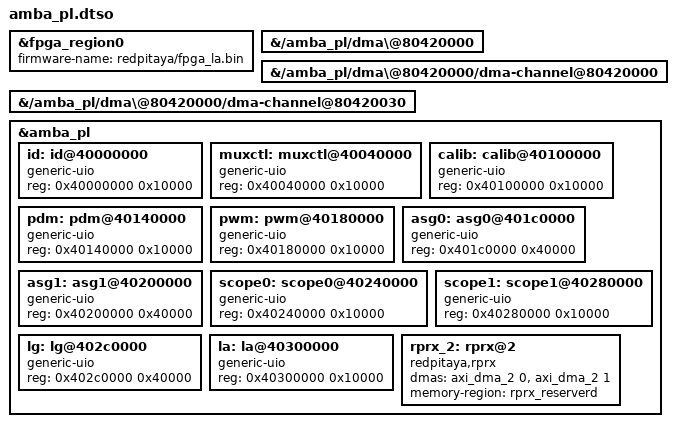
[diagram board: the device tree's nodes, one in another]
/dts-v1/;
/plugin/;
/{
		fragment@0 {
				target = <&fpga_region0>;
				#address-cells = <1>;
				#size-cells = <1>;

				__overlay__ {
					#address-cells = <1>;
					#size-cells = <1>;
					firmware-name = "redpitaya/fpga_la.bin";
				};
		};
		
		fragment@1 {
		target-path = "/amba_pl/dma\@80420000";
			__overlay__ {
						status = "okay";
				};
		};
		fragment@2 {
		target-path = "/amba_pl/dma\@80420000/dma-channel@80420000";
			__overlay__ {
						status = "okay";
				};
		};
		fragment@3 {
		target-path = "/amba_pl/dma\@80420000/dma-channel@80420030";
			__overlay__ {
						status = "okay";
				};
		};
		fragment@4{
			target = <&amba_pl>;
			__overlay__ {
				id: id@40000000 {
					compatible = "generic-uio";
					reg = <0x40000000 0x10000>;
					status = "okay";
					};
			};
		};
		fragment@5{
			target = <&amba_pl>;
			__overlay__ {
			muxctl: muxctl@40040000 {
				compatible = "generic-uio";
				reg = <0x40040000 0x10000>;
				status = "okay";
				};
			};
		};
		fragment@8{
			target = <&amba_pl>;
			__overlay__ {
				calib: calib@40100000 {
					compatible = "generic-uio";
					reg = <0x40100000 0x10000>;
					status = "okay";
				};
			};
		};
		fragment@9{
			target = <&amba_pl>;
			__overlay__ {
				pdm: pdm@40140000 {
					compatible = "generic-uio";
					reg = <0x40140000 0x10000>;
					status = "okay";
				};
			};
		};
		fragment@a{
			target = <&amba_pl>;
			__overlay__ {
				pwm: pwm@40180000 {
					compatible = "generic-uio";
					reg = <0x40180000 0x10000>;
					status = "okay";
					};

				};
		};
		fragment@b{
			target = <&amba_pl>;
			__overlay__ {
				asg0: asg0@401c0000 {
					compatible = "generic-uio";
					reg = <0x401c0000 0x40000>;
					status = "okay";
				};
			};
		};
		fragment@c{
			target = <&amba_pl>;
			__overlay__ {
			
				asg1: asg1@40200000 {
						compatible = "generic-uio";
						reg = <0x40200000 0x40000>;
						status = "okay";
					};
				};
		};
		fragment@d{
			target = <&amba_pl>;
			__overlay__ {
				scope0: scope0@40240000 {
					compatible = "generic-uio";
					reg = <0x40240000 0x10000>;
					status = "okay";
				};
			};
		};
		fragment@e{
			target = <&amba_pl>;
			__overlay__ {
				scope1: scope1@40280000 {
					compatible = "generic-uio";
					reg = <0x40280000 0x10000>;
					status = "okay";
				};
			};
		};
		fragment@f{
			target = <&amba_pl>;
			__overlay__ {
				lg: lg@402c0000 {
					compatible = "generic-uio";
					reg = <0x402c0000 0x40000>;
					status = "okay";
				};
			};
		};
		fragment@10{
			target = <&amba_pl>;
			__overlay__ {
				la: la@40300000 {
					compatible = "generic-uio";
					reg = <0x40300000 0x10000>;
					status = "okay";
				};
			};
		};
		fragment@11{
			target = <&amba_pl>;
			__overlay__ {
			rprx_2: rprx@2 {
				compatible ="redpitaya,rprx";
				dmas = <&axi_dma_2 0
						&axi_dma_2 1>;
				dma-names = "axidma0", "axidma1";
				memory-region = <&rprx_reserverd>;
				status = "okay";
			};
			};
		};
};
//compile overlay
//dtc -O dtb -o amba_pl.dtbo -b 0 -@ amba_pl.dts
//preprair
//mkdir /sys/kernel/config/device-tree/overlays/amba_pl
//apply
//cat amba_pl.dtbo > /sys/kernel/config/device-tree/overlays/amba_pl/dtbo
//remove
//rmdir /sys/kernel/config/device-tree/overlays/amba_pl
